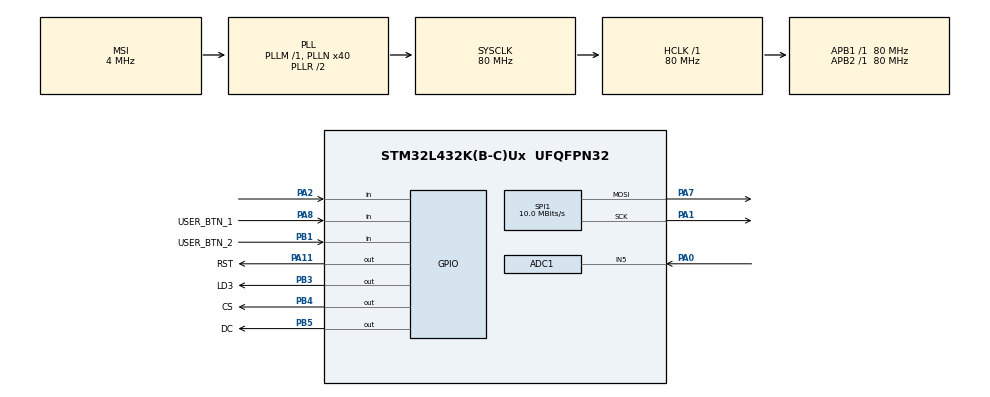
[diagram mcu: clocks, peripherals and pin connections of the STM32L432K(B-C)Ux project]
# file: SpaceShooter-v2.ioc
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ADC1.Channel-0\#ChannelRegularConversion=ADC_CHANNEL_5
ADC1.ContinuousConvMode=ENABLE
ADC1.DMAContinuousRequests=DISABLE
ADC1.NbrOfConversion=1
ADC1.NbrOfConversionFlag=1
ADC1.OffsetNumber-0\#ChannelRegularConversion=ADC_OFFSET_NONE
ADC1.Overrun=ADC_OVR_DATA_OVERWRITTEN
ADC1.OversamplingMode=DISABLE
ADC1.Rank-0\#ChannelRegularConversion=1
ADC1.SamplingTime-0\#ChannelRegularConversion=ADC_SAMPLETIME_640CYCLES_5
ADC1.master=1
Dma.Request0=SPI1_TX
Dma.SPI1_TX.0.Direction=DMA_MEMORY_TO_PERIPH
Dma.SPI1_TX.0.Instance=DMA1_Channel3
Dma.SPI1_TX.0.MemDataAlignment=DMA_MDATAALIGN_BYTE
Dma.SPI1_TX.0.MemInc=DMA_MINC_ENABLE
Dma.SPI1_TX.0.Mode=DMA_NORMAL
Dma.SPI1_TX.0.PeriphDataAlignment=DMA_PDATAALIGN_BYTE
Dma.SPI1_TX.0.PeriphInc=DMA_PINC_DISABLE
Dma.SPI1_TX.0.Priority=DMA_PRIORITY_LOW
Mcu.Family=STM32L4
Mcu.Name=STM32L432K(B-C)Ux
Mcu.Package=UFQFPN32
NVIC.DMA1_Channel3_IRQn=true\:0\:0\:false\:true\:true\:1\:true\:true\:true
NVIC.PriorityGroup=NVIC_PRIORITYGROUP_4
NVIC.SPI1_IRQn=true\:0\:0\:false\:true\:true\:2\:true\:true\:true
NVIC.TIM6_DAC_IRQn=true\:10\:0\:true\:true\:true\:3\:true\:true\:true
PA0.Signal=ADCx_IN5
PA1.Mode=TX_Only_Simplex_Unidirect_Master
PA1.Signal=SPI1_SCK
PA11.GPIO_Label=RST
PA11.Signal=GPIO_Output
PA2.GPIO_PuPd=GPIO_PULLUP
PA2.Signal=GPIO_Input
PA7.Mode=TX_Only_Simplex_Unidirect_Master
PA7.Signal=SPI1_MOSI
PA8.GPIO_Label=USER_BTN_1
PA8.GPIO_PuPd=GPIO_PULLDOWN
PA8.Signal=GPIO_Input
PB1.GPIO_Label=USER_BTN_2
PB1.GPIO_PuPd=GPIO_PULLDOWN
PB1.Signal=GPIO_Input
PB3\ (JTDO-TRACESWO).GPIO_Label=LD3
PB3\ (JTDO-TRACESWO).Signal=GPIO_Output
PB4\ (NJTRST).GPIO_Label=CS
PB4\ (NJTRST).Signal=GPIO_Output
PB5.GPIO_Label=DC
PB5.Signal=GPIO_Output
PC14-OSC32_IN\ (PC14).Mode=LSE-External-Oscillator
PC14-OSC32_IN\ (PC14).Signal=RCC_OSC32_IN
PC15-OSC32_OUT\ (PC15).Mode=LSE-External-Oscillator
PC15-OSC32_OUT\ (PC15).Signal=RCC_OSC32_OUT
ProjectManager.HeapSize=0x200
ProjectManager.StackSize=0x400
ProjectManager.TargetToolchain=STM32CubeIDE
RCC.ADCFreq_Value=32000000
RCC.AHBFreq_Value=80000000
RCC.APB1Freq_Value=80000000
RCC.APB1TimFreq_Value=80000000
RCC.APB2Freq_Value=80000000
RCC.APB2TimFreq_Value=80000000
RCC.CortexFreq_Value=80000000
RCC.HCLKFreq_Value=80000000
RCC.HSE_VALUE=8000000
RCC.HSI48_VALUE=48000000
RCC.HSI_VALUE=16000000
RCC.MSI_VALUE=4000000
RCC.PLLN=40
RCC.PLLSAI1N=16
RCC.SYSCLKFreq_VALUE=80000000
RCC.SYSCLKSource=RCC_SYSCLKSOURCE_PLLCLK
RCC.USBFreq_Value=32000000
RCC.VCOOutputFreq_Value=160000000
SH.ADCx_IN5.0=ADC1_IN5,IN5-Single-Ended
SPI1.BaudRatePrescaler=SPI_BAUDRATEPRESCALER_8
SPI1.CalculateBaudRate=10.0 MBits/s
SPI1.DataSize=SPI_DATASIZE_8BIT
SPI1.Direction=SPI_DIRECTION_2LINES
SPI1.Mode=SPI_MODE_MASTER
SPI1.VirtualType=VM_MASTER
TIM6.Period=80
TIM6.Prescaler=7999
VP_TIM6_VS_ClockSourceINT.Mode=Enable_Timer
board=custom

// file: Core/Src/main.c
/* USER CODE BEGIN Header */
/**
 ******************************************************************************
 * @file           : main.c
 * @brief          : Main program body
 ******************************************************************************
 * @attention
 *
 * Copyright (c) 2022 STMicroelectronics.
 * All rights reserved.
 *
 * This software is licensed under terms that can be found in the LICENSE file
 * in the root directory of this software component.
 * If no LICENSE file comes with this software, it is provided AS-IS.
 *
 ******************************************************************************
 *
 * @todo
 * - Adding bonuses: quick shots, protective shield.
 * - Addition of storyline breakers and storyline introduction.
 *
 *
 ******************************************************************************
 */

/* USER CODE END Header */
#include "main.h"
#include "adc.h"
#include "dma.h"
#include "spi.h"
#include "tim.h"
#include "gpio.h"

/* USER CODE BEGIN Includes */

#include "app/app.h"
#include <stdbool.h>
#include <stdlib.h>

/* USER CODE END Includes */

/* USER CODE BEGIN PV */

static AppCtx g_app;

/* USER CODE END PV */

void SystemClock_Config(void);
static void MX_NVIC_Init(void);

int main(void) {

	/* MCU Configuration--------------------------------------------------------*/

	/* Reset of all peripherals, Initializes the Flash interface and the Systick. */
	HAL_Init();

	/* Configure the system clock */
	SystemClock_Config();

	/* Initialize all configured peripherals */
	MX_GPIO_Init();
	MX_DMA_Init();
	MX_ADC1_Init();
	MX_SPI1_Init();
	MX_TIM6_Init();

	/* Initialize interrupts */
	MX_NVIC_Init();
	/* USER CODE BEGIN 2 */

//  // Konfiguracja ADC z DMA
//  HAL_ADCEx_Calibration_Start(&hadc1, ADC_SINGLE_ENDED);
//  HAL_ADC_Start_DMA(&hadc1, (uint32_t*)value, 2);
	HAL_ADCEx_Calibration_Start(&hadc1, ADC_SINGLE_ENDED);
	HAL_ADC_Start(&hadc1);
	HAL_TIM_Base_Start_IT(&htim6);

	/* USER CODE END 2 */

	/* Infinite loop */
	/* USER CODE BEGIN WHILE */

	App_Init(&g_app, &g_singleton, &hspi1, &hadc1,
	USER_BTN_1_GPIO_Port, USER_BTN_1_Pin,
	USER_BTN_2_GPIO_Port, USER_BTN_2_Pin);

	while (1) {
		App_RunOnce(&g_app);
		/* USER CODE END WHILE */

	}
}

void SystemClock_Config(void) {
	RCC_OscInitTypeDef RCC_OscInitStruct = { 0 };
	RCC_ClkInitTypeDef RCC_ClkInitStruct = { 0 };

	/** Configure the main internal regulator output voltage
	 */
	if (HAL_PWREx_ControlVoltageScaling(PWR_REGULATOR_VOLTAGE_SCALE1)
			!= HAL_OK) {
		Error_Handler();
	}

	/** Configure LSE Drive Capability
	 */
	HAL_PWR_EnableBkUpAccess();
	__HAL_RCC_LSEDRIVE_CONFIG(RCC_LSEDRIVE_LOW);

	/** Initializes the RCC Oscillators according to the specified parameters
	 * in the RCC_OscInitTypeDef structure.
	 */
	RCC_OscInitStruct.OscillatorType = RCC_OSCILLATORTYPE_LSE
			| RCC_OSCILLATORTYPE_MSI;
	RCC_OscInitStruct.LSEState = RCC_LSE_ON;
	RCC_OscInitStruct.MSIState = RCC_MSI_ON;
	RCC_OscInitStruct.MSICalibrationValue = 0;
	RCC_OscInitStruct.MSIClockRange = RCC_MSIRANGE_6;
	RCC_OscInitStruct.PLL.PLLState = RCC_PLL_ON;
	RCC_OscInitStruct.PLL.PLLSource = RCC_PLLSOURCE_MSI;
	RCC_OscInitStruct.PLL.PLLM = 1;
	RCC_OscInitStruct.PLL.PLLN = 40;
	RCC_OscInitStruct.PLL.PLLP = RCC_PLLP_DIV7;
	RCC_OscInitStruct.PLL.PLLQ = RCC_PLLQ_DIV2;
	RCC_OscInitStruct.PLL.PLLR = RCC_PLLR_DIV2;
	if (HAL_RCC_OscConfig(&RCC_OscInitStruct) != HAL_OK) {
		Error_Handler();
	}

	/** Initializes the CPU, AHB and APB buses clocks
	 */
	RCC_ClkInitStruct.ClockType = RCC_CLOCKTYPE_HCLK | RCC_CLOCKTYPE_SYSCLK
			| RCC_CLOCKTYPE_PCLK1 | RCC_CLOCKTYPE_PCLK2;
	RCC_ClkInitStruct.SYSCLKSource = RCC_SYSCLKSOURCE_PLLCLK;
	RCC_ClkInitStruct.AHBCLKDivider = RCC_SYSCLK_DIV1;
	RCC_ClkInitStruct.APB1CLKDivider = RCC_HCLK_DIV1;
	RCC_ClkInitStruct.APB2CLKDivider = RCC_HCLK_DIV1;

	if (HAL_RCC_ClockConfig(&RCC_ClkInitStruct, FLASH_LATENCY_4) != HAL_OK) {
		Error_Handler();
	}

	/** Enable MSI Auto calibration
	 */
	HAL_RCCEx_EnableMSIPLLMode();
}

/**
 * @brief NVIC Configuration.
 * @retval None
 */
static void MX_NVIC_Init(void) {
	/* DMA1_Channel3_IRQn interrupt configuration */
	HAL_NVIC_SetPriority(DMA1_Channel3_IRQn, 0, 0);
	HAL_NVIC_EnableIRQ(DMA1_Channel3_IRQn);
	/* SPI1_IRQn interrupt configuration */
	HAL_NVIC_SetPriority(SPI1_IRQn, 0, 0);
	HAL_NVIC_EnableIRQ(SPI1_IRQn);
	/* TIM6_DAC_IRQn interrupt configuration */
	HAL_NVIC_SetPriority(TIM6_DAC_IRQn, 10, 0);
	HAL_NVIC_EnableIRQ(TIM6_DAC_IRQn);
}

/* USER CODE BEGIN 4 */

void HAL_TIM_PeriodElapsedCallback(TIM_HandleTypeDef *htim) {
	if (htim->Instance == TIM6) {
		App_OnTimerTick(&g_app);
	}
}

/* USER CODE END 4 */

void Error_Handler(void) {
	__disable_irq();
	while (1) {
	}
}
